# STM32H7S register map
File version: 1.3
CPU: CM7 r0p1, little endian, MPU, FPU, 4 interrupt priority bits
Registers are 32-bit, read-write, reset 0x0 unless marked. A register's access mark holds for its fields unless they carry their own. Offsets are from the block's base; [hi:lo] are bit positions; {n}, {i} and the like mark numbered series.

## EXTI — Extended interrupt and event controller
Base 0x58000000
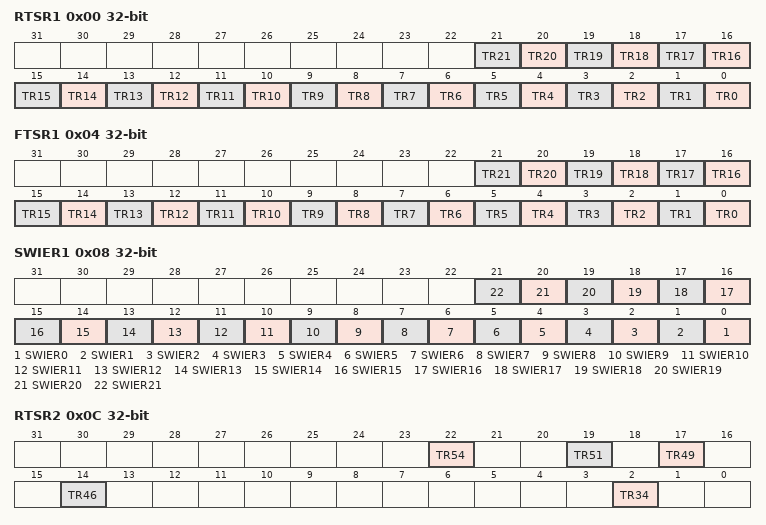
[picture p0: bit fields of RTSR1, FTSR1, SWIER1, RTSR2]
0x00 RTSR1 — EXTI rising trigger selection register
  [n] TR{n} (n=0..21) — Rising trigger event configuration bit of configurable event input x.
0x04 FTSR1 — EXTI falling trigger selection register
  [n] TR{n} (n=0..21) — Falling trigger event configuration bit of configurable event input x.
0x08 SWIER1 — EXTI software interrupt event register
  [n] SWIER{n} (n=0..21) — Software interrupt on line x This bitfield alway returns 0 when read.
0x0C RTSR2 — EXTI rising trigger selection register
  [22] TR54 — Rising trigger event configuration bit of configurable event input x+32.
  [19] TR51 — Rising trigger event configuration bit of configurable event input x+32.<sup>(1)</sup>
  [17] TR49 — Rising trigger event configuration bit of configurable event input x+32.<sup>(1)</sup>
  [14] TR46 — Rising trigger event configuration bit of configurable event input x+32.<sup>(1)</sup>
  [2] TR34 — Rising trigger event configuration bit of configurable event input x+32.<sup>(1)</sup>
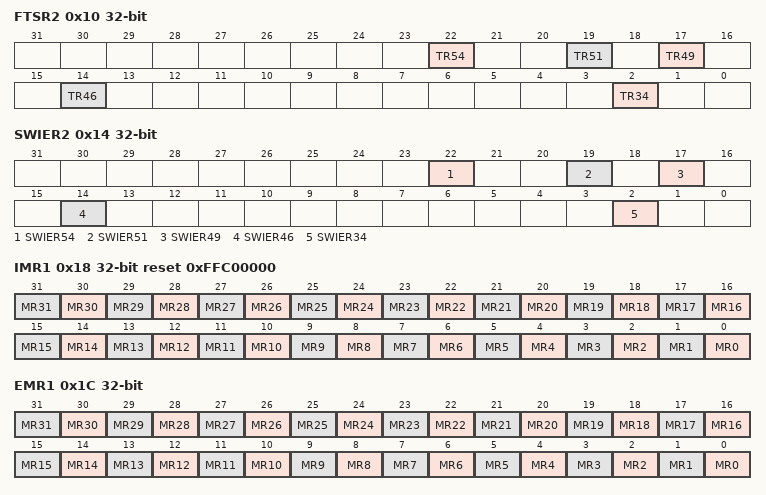
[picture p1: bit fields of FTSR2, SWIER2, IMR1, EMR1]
0x10 FTSR2 — EXTI falling trigger selection register
  [22] TR54 — Falling trigger event configuration bit of configurable event input x+32.
  [19] TR51 — Falling trigger event configuration bit of configurable event input x+32.<sup>(1)</sup>
  [17] TR49 — Falling trigger event configuration bit of configurable event input x+32.<sup>(1)</sup>
  [14] TR46 — Falling trigger event configuration bit of configurable event input x+32.<sup>(1)</sup>
  [2] TR34 — Falling trigger event configuration bit of configurable event input x+32.<sup>(1)</sup>
0x14 SWIER2 — EXTI software interrupt event register
  [22] SWIER54 — Software interrupt on line x+32 Always returns 0 when read.
  [19] SWIER51 — Software interrupt on line x+32 Always returns 0 when read.
  [17] SWIER49 — Software interrupt on line x+32 Always returns 0 when read.
  [14] SWIER46 — Software interrupt on line x+32 Always returns 0 when read.
  [2] SWIER34 — Software interrupt on line x+32 Always returns 0 when read.
0x18 IMR1 reset 0xFFC00000 — EXTI interrupt mask register
  [n] MR{n} (n=22..31) — CPU interrupt mask on direct event input x
  [n] MR{n} (n=0..21) — CPU interrupt mask on configurable event input x
0x1C EMR1 — EXTI event mask register
  [n] MR{n} (n=0..31) — CPU event mask on event input x
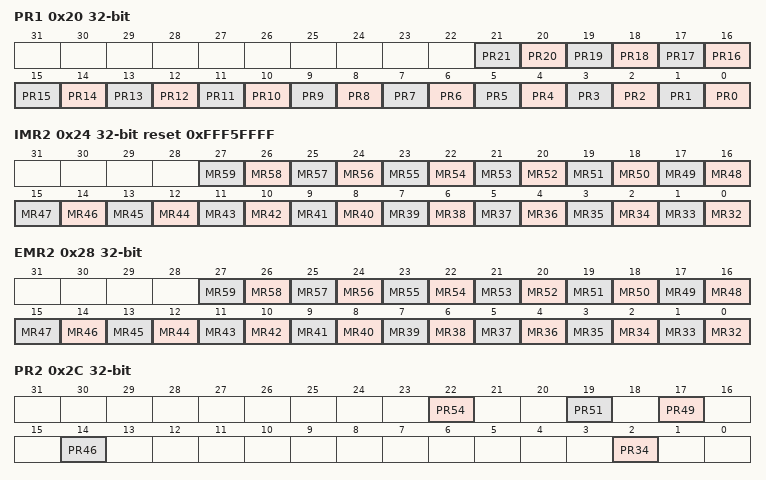
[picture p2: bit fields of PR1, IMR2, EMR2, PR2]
0x20 PR1 reset not defined — EXTI pending register
  [n] PR{n} (n=0..21) — Configurable event inputs x Pending bit This bit is set when the selected edge event arrives on the external interrupt line. This bit is cleared by writing a 1 into the bit or by changing the sensitivity of the edge detector.
0x24 IMR2 reset 0xFFF5FFFF — EXTI interrupt mask register
  [n-32] MR{n} (n=32..59) — CPU interrupt mask on direct event input i
0x28 EMR2 — EXTI event mask register
  [n-32] MR{n} (n=32..59) — CPU event mask on event input i
0x2C PR2 reset not defined — EXTI pending register
  [22] PR54 — Configurable event inputs x+32 Pending bit This bit is set when the selected edge event arrives on the external interrupt line. This bit is cleared by writing a 1 into the bit or by changing the sensitivity of the edge detector.
  [19] PR51 — Configurable event inputs x+32 Pending bit This bit is set when the selected edge event arrives on the external interrupt line. This bit is cleared by writing a 1 into the bit or by changing the sensitivity of the edge detector.
  [17] PR49 — Configurable event inputs x+32 Pending bit This bit is set when the selected edge event arrives on the external interrupt line. This bit is cleared by writing a 1 into the bit or by changing the sensitivity of the edge detector.
  [14] PR46 — Configurable event inputs x+32 Pending bit This bit is set when the selected edge event arrives on the external interrupt line. This bit is cleared by writing a 1 into the bit or by changing the sensitivity of the edge detector.
  [2] PR34 — Configurable event inputs x+32 Pending bit This bit is set when the selected edge event arrives on the external interrupt line. This bit is cleared by writing a 1 into the bit or by changing the sensitivity of the edge detector.
0x30 IMR3 reset 0xF8BFFFF — EXTI interrupt mask register
  [13] MR77 — CPU interrupt mask on direct event input x+64
0x34 EMR3 — EXTI event mask register
  [13] MR77 — CPU event mask on event input x+64
